# ATSAMD21G16L device description
Architecture: CORTEX-M0PLUS; Family: SAMD; Series: SAMD21
Registers are 32-bit, read-write, reset 0x0 unless marked. A register's access mark holds for its fields unless they carry their own. Offsets are from the block's base; [hi:lo] are bit positions; lines under a group give offsets from that group; {n}, {i} and the like mark numbered series; 'fields as' and 'values as' point back to an identical list.

## PORT — Port Module
Instances: PORT 0x41004400, PORT_IOBUS 0x60000000
{0x0+0x80*i} GROUP[{i}] (i=0..1) group
  0x00 DIR — Data Direction
    [31:0] DIR — Port Data Direction
  0x04 DIRCLR (atomic clear of DIR) — Data Direction Clear
    [31:0] DIRCLR — Port Data Direction Clear
  0x08 DIRSET (atomic set of DIR) — Data Direction Set
    [31:0] DIRSET — Port Data Direction Set
  0x0C DIRTGL (atomic toggle of DIR) — Data Direction Toggle
    [31:0] DIRTGL — Port Data Direction Toggle
  0x10 OUT — Data Output Value
    [31:0] OUT — Port Data Output Value
  0x14 OUTCLR (atomic clear of OUT) — Data Output Value Clear
    [31:0] OUTCLR — Port Data Output Value Clear
  0x18 OUTSET (atomic set of OUT) — Data Output Value Set
    [31:0] OUTSET — Port Data Output Value Set
  0x1C OUTTGL (atomic toggle of OUT) — Data Output Value Toggle
    [31:0] OUTTGL — Port Data Output Value Toggle
  0x20 IN ro — Data Input Value
    [31:0] IN — Port Data Input Value
  0x24 CTRL — Control
    [31:0] SAMPLING — Input Sampling Mode
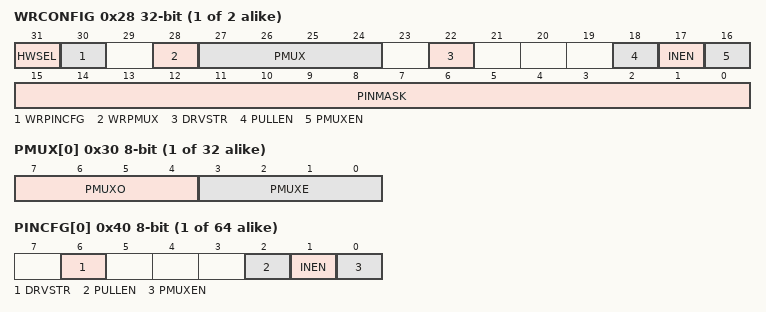
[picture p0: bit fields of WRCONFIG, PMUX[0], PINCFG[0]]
  0x28 WRCONFIG wo — Write Configuration
    [31] HWSEL — Half-Word Select
    [30] WRPINCFG — Write PINCFG
    [28] WRPMUX — Write PMUX
    [27:24] PMUX — Peripheral Multiplexing
    [22] DRVSTR — Output Driver Strength Selection
    [18] PULLEN — Pull Enable
    [17] INEN — Input Enable
    [16] PMUXEN — Peripheral Multiplexer Enable
    [15:0] PINMASK — Pin Mask for Multiple Pin Configuration
  {0x30+j} PMUX[{j}] (j=0..15) 8-bit — Peripheral Multiplexing n
    [7:4] PMUXO — Peripheral Multiplexing Odd
      0=A (Peripheral function A selected); 1=B (Peripheral function B selected); 2=C (Peripheral function C selected); 3=D (Peripheral function D selected); 4=E (Peripheral function E selected); 5=F (Peripheral function F selected); 6=G (Peripheral function G selected); 7=H (Peripheral function H selected)
    [3:0] PMUXE — Peripheral Multiplexing Even
      values as PMUXO
  {0x40+j} PINCFG[{j}] (j=0..31) 8-bit — Pin Configuration n
    [6] DRVSTR — Output Driver Strength Selection
    [2] PULLEN — Pull Enable
    [1] INEN — Input Enable
    [0] PMUXEN — Peripheral Multiplexer Enable

## WDT — Watchdog Timer
Instances: WDT 0x40001000
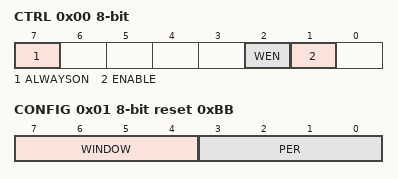
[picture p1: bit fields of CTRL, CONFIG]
0x00 CTRL 8-bit (WSYNC) — Control
  [7] ALWAYSON
  [2] WEN — Watchdog Timer Window Mode Enable
  [1] ENABLE
0x01 CONFIG 8-bit reset 0xBB (WSYNC) — Configuration
  [7:4] WINDOW — Window Mode Time-Out Period
    0=8 clock cycles; 1=16 clock cycles; 2=32 clock cycles; 3=64 clock cycles; 4=128 clock cycles; 5=256 clock cycles; 6=512 clock cycles; 7=1K (1024 clock cycles); 8=2K (2048 clock cycles); 9=4K (4096 clock cycles); 10=8K (8192 clock cycles); 11=16K (16384 clock cycles)
  [3:0] PER — Time-Out Period
    values as WINDOW
0x02 EWCTRL 8-bit reset 0xB — Early Warning Interrupt Control
  [3:0] EWOFFSET — Early Warning Interrupt Time Offset
    values as CONFIG.WINDOW
0x04 INTENCLR 8-bit (atomic clear) — Interrupt Enable Clear
  [0] EW — Early Warning Interrupt Enable
0x05 INTENSET 8-bit (atomic set) — Interrupt Enable Set
  [0] EW — Early Warning Interrupt Enable
0x06 INTFLAG 8-bit (atomic clear) — Interrupt Flag Status and Clear
  [0] EW — Early Warning
0x07 STATUS 8-bit ro
  [7] SYNCBUSY — Synchronization Busy
0x08 CLEAR 8-bit wo (WSYNC)
  [7:0] CLEAR — Watchdog Clear
    165=KEY (Clear Key)

## SystemControl — System Control Registers
Instances: SystemControl 0xE000E000
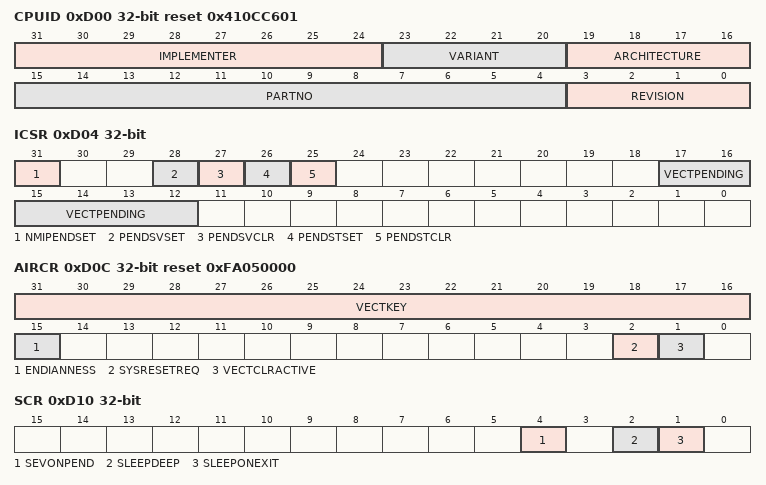
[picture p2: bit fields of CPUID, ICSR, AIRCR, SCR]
0xD00 CPUID access not given reset 0x410CC601 — CPUID Base Register
  [31:24] IMPLEMENTER — Implementer code
  [23:20] VARIANT — Indicates processor revision: 0x2 = Revision 2
  [19:16] ARCHITECTURE — Constant that defines the architecture of the processor
  [15:4] PARTNO — Indicates part number
  [3:0] REVISION — Indicates patch release: 0x0 = Patch 0
0xD04 ICSR access not given — Interrupt Control and State Register
  [31] NMIPENDSET
    0=write: no effect; read: NMI exception is not pending; 1=write: changes NMI exception state to pending; read: NMI exception is pending
  [28] PENDSVSET
    0=write: no effect; read: PendSV exception is not pending; 1=write: changes PendSV exception state to pending; read: PendSV exception is pending
  [27] PENDSVCLR
    0=no effect; 1=removes the pending state from the PendSV exception
  [26] PENDSTSET
    0=write: no effect; read: SysTick exception is not pending; 1=write: changes SysTick exception state to pending; read: SysTick exception is pending
  [25] PENDSTCLR
    0=no effect; 1=removes the pending state from the SysTick exception
  [17:12] VECTPENDING — Exception number of the highest priority pending enabled exception
0xD08 VTOR access not given — Vector Table Offset Register
  [31:7] TBLOFF — Vector table base offset
0xD0C AIRCR access not given reset 0xFA050000 — Application Interrupt and Reset Control Register
  [31:16] VECTKEY — Register key
  [15] ENDIANNESS
    0=Little-endian; 1=Big-endian
  [2] SYSRESETREQ
    0=no system reset request; 1=asserts a signal to the outer system that requests a reset
  [1] VECTCLRACTIVE
0xD10 SCR access not given — System Control Register
  [4] SEVONPEND
    0=only enabled interrupts or events can wakeup the processor, disabled interrupts are excluded; 1=enabled events and all interrupts, including disabled interrupts, can wakeup the processor
  [2] SLEEPDEEP
    0=sleep; 1=deep sleep
  [1] SLEEPONEXIT
    0=o not sleep when returning to Thread mode; 1=enter sleep, or deep sleep, on return from an ISR
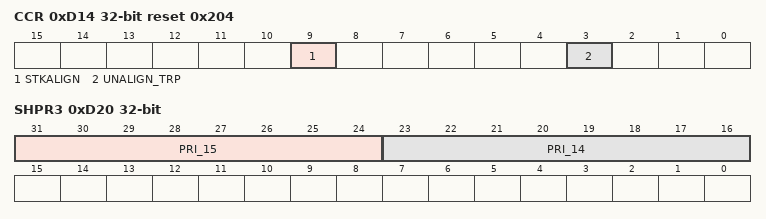
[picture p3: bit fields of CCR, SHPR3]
0xD14 CCR access not given reset 0x204 — Configuration and Control Register
  [9] STKALIGN — Indicates stack alignment on exception entry
    0=4-byte aligned; 1=8-byte aligned
  [3] UNALIGN_TRP — Enables unaligned access traps
    0=do not trap unaligned halfword and word accesses; 1=trap unaligned halfword and word accesses
0xD1C SHPR2 access not given — System Handler Priority Register 2
  [31:24] PRI_11 — Priority of system handler 11, SVCall
0xD20 SHPR3 access not given — System Handler Priority Register 3
  [31:24] PRI_15 — Priority of system handler 15, SysTick exception
  [23:16] PRI_14 — Priority of system handler 14, PendSV

## SysTick — System timer
Instances: SysTick 0xE000E010
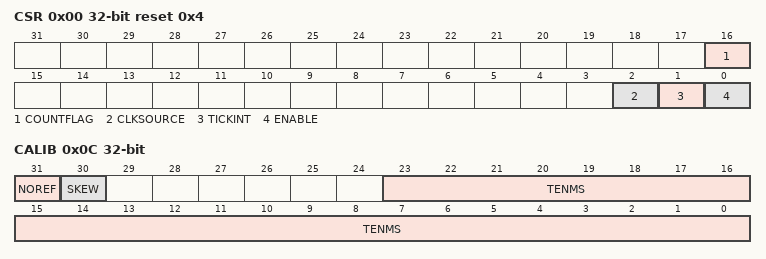
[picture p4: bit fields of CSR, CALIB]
0x00 CSR access not given reset 0x4 — SysTick Control and Status Register
  [16] COUNTFLAG
  [2] CLKSOURCE
    0=external clock; 1=processor clock
  [1] TICKINT
    0=counting down to 0 does not assert the SysTick exception request; 1=counting down to 0 asserts the SysTick exception request
  [0] ENABLE
    0=counter disabled; 1=counter enabled
0x04 RVR access not given — SysTick Reload Value Register
  [23:0] RELOAD — Value to load into the SysTick Current Value Register when the counter reaches 0
0x08 CVR access not given — SysTick Current Value Register
  [23:0] CURRENT — Current value at the time the register is accessed
0x0C CALIB access not given — SysTick Calibration Value Register
  [31] NOREF
    0=The reference clock is provided; 1=The reference clock is not provided
  [30] SKEW
    0=10ms calibration value is exact; 1=10ms calibration value is inexact, because of the clock frequency
  [23:0] TENMS — Reload value to use for 10ms timing

## NVIC — Nested Vectored Interrupt Controller
Instances: NVIC 0xE000E100
0x00 NVICISER access not given — Interrupt Set Enable Register
  [31:0] SETENA — Interrupt set enable bits
0x80 NVICICER access not given — Interrupt Clear Enable Register
  [31:0] CLRENA — Interrupt clear-enable bits
0x100 NVICISPR access not given — Interrupt Set Pending Register
  [31:0] SETPEND — Interrupt set-pending bits
0x180 NVICICPR access not given — Interrupt Clear Pending Register
  [31:0] CLRPEND — Interrupt clear-pending bits
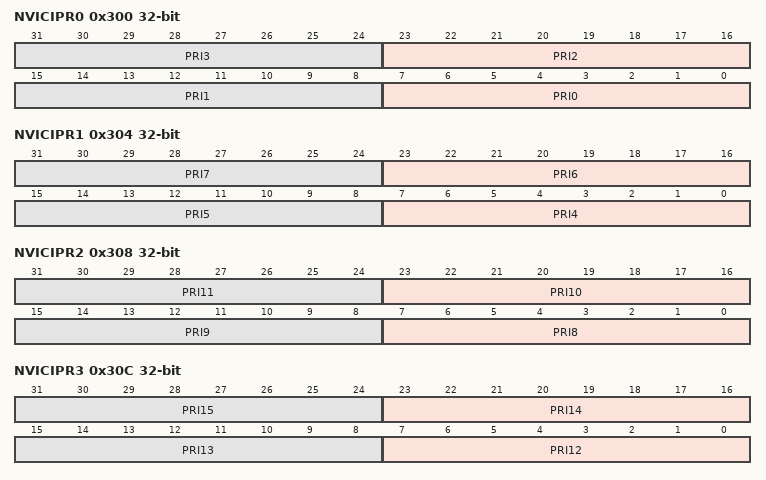
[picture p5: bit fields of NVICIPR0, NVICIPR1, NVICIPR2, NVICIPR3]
0x300 NVICIPR0 access not given — Interrupt Priority Register 0
  [8n+7:8n] PRI{n} (n=0..3) — Priority of interrupt {n}
0x304 NVICIPR1 access not given — Interrupt Priority Register 1
  [8n-25:8n-32] PRI{n} (n=4..7) — Priority of interrupt {n}
0x308 NVICIPR2 access not given — Interrupt Priority Register 2
  [8n-57:8n-64] PRI{n} (n=8..11) — Priority of interrupt {n}
0x30C NVICIPR3 access not given — Interrupt Priority Register 3
  [8n-89:8n-96] PRI{n} (n=12..15) — Priority of interrupt {n}
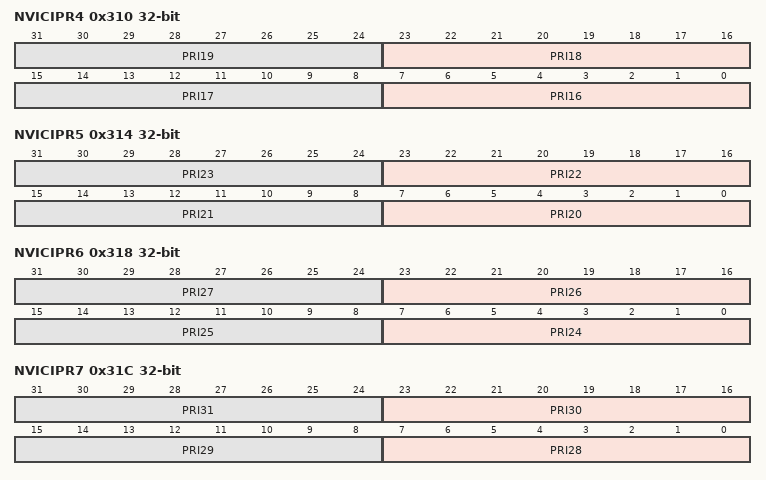
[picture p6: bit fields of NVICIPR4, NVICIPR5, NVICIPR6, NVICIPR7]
0x310 NVICIPR4 access not given — Interrupt Priority Register 4
  [8n-121:8n-128] PRI{n} (n=16..19) — Priority of interrupt {n}
0x314 NVICIPR5 access not given — Interrupt Priority Register 5
  [8n-153:8n-160] PRI{n} (n=20..23) — Priority of interrupt {n}
0x318 NVICIPR6 access not given — Interrupt Priority Register 6
  [8n-185:8n-192] PRI{n} (n=24..27) — Priority of interrupt {n}
0x31C NVICIPR7 access not given — Interrupt Priority Register 7
  [8n-217:8n-224] PRI{n} (n=28..31) — Priority of interrupt {n}

## Notices in the file
Copyright (c) 2017 Atmel Corporation,
a wholly owned subsidiary of Microchip Technology Inc.
Licensed under the Apache License, Version 2.0 (the "License");
you may not use this file except in compliance with the License.
You may obtain a copy of the Licence at
http://www.apache.org/licenses/LICENSE-2.0
Unless required by applicable law or agreed to in writing, software
distributed under the License is distributed on an "AS IS" BASIS,
WITHOUT WARRANTIES OR CONDITIONS OF ANY KIND, either express or implied.
See the License for the specific language governing permissions and
limitations under the License.
